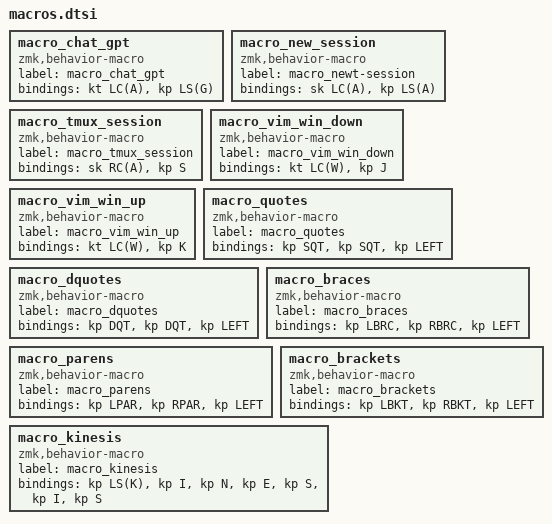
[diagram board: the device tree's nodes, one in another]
macro_chat_gpt: macro_chat_gpt{
compatible = "zmk,behavior-macro";
label = "macro_chat_gpt";
#binding-cells = <0>;
bindings = <&kt LC(A)>, <&kp LS(G)>;
};
macro_new_session: macro_new_session{
compatible = "zmk,behavior-macro";
label = "macro_newt-session";
#binding-cells = <0>;
bindings = <&sk LC(A)>, <&kp LS(A)>;
};
macro_tmux_session: macro_tmux_session{
compatible = "zmk,behavior-macro";
label = "macro_tmux_session";
#binding-cells = <0>;
bindings = <&sk RC(A)>, <&kp S>;
};
macro_vim_win_down: macro_vim_win_down{
compatible = "zmk,behavior-macro";
label = "macro_vim_win_down";
#binding-cells = <0>;
bindings = <&kt LC(W)>, <&kp J>;
};
macro_vim_win_up: macro_vim_win_up{
compatible = "zmk,behavior-macro";
label = "macro_vim_win_up";
#binding-cells = <0>;
bindings = <&kt LC(W)>, <&kp K>;
};
macro_quotes: macro_quotes{
compatible = "zmk,behavior-macro";
label = "macro_quotes";
#binding-cells = <0>;
bindings = <&kp SQT>, <&kp SQT>, <&kp LEFT>;
};
macro_dquotes: macro_dquotes{
compatible = "zmk,behavior-macro";
label = "macro_dquotes";
#binding-cells = <0>;
bindings = <&kp DQT>, <&kp DQT>, <&kp LEFT>;
};
macro_braces: macro_braces{
compatible = "zmk,behavior-macro";
label = "macro_braces";
#binding-cells = <0>;
bindings = <&kp LBRC>, <&kp RBRC>, <&kp LEFT>;
};
macro_parens: macro_parens{
compatible = "zmk,behavior-macro";
label = "macro_parens";
#binding-cells = <0>;
bindings = <&kp LPAR>, <&kp RPAR>, <&kp LEFT>;
};
macro_brackets: macro_brackets{
compatible = "zmk,behavior-macro";
label = "macro_brackets";
#binding-cells = <0>;
bindings = <&kp LBKT>, <&kp RBKT>, <&kp LEFT>;
};
macro_kinesis: macro_kinesis{
compatible = "zmk,behavior-macro";
label = "macro_kinesis";
#binding-cells = <0>;
bindings = <&kp LS(K)>, <&kp I>, <&kp N>, <&kp E>, <&kp S>, <&kp I>, <&kp S>;
};
